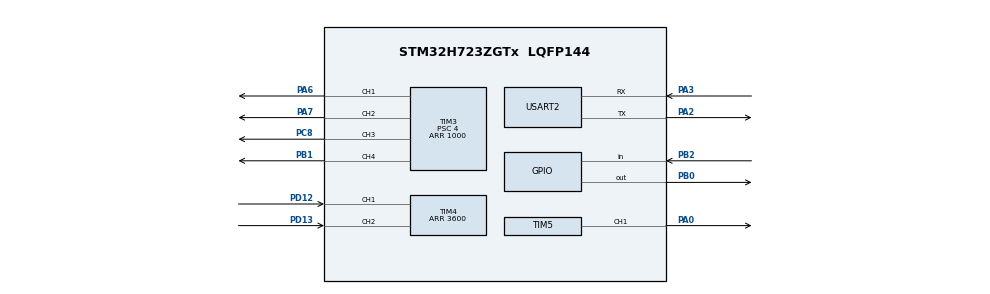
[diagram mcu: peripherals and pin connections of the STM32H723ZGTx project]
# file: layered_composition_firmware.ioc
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CORTEX_M7.default_mode_Activation=1
Dma.Request0=USART2_RX
Dma.Request1=USART2_TX
Dma.USART2_RX.0.Direction=DMA_PERIPH_TO_MEMORY
Dma.USART2_RX.0.EventEnable=DISABLE
Dma.USART2_RX.0.FIFOMode=DMA_FIFOMODE_DISABLE
Dma.USART2_RX.0.Instance=DMA1_Stream0
Dma.USART2_RX.0.MemDataAlignment=DMA_MDATAALIGN_BYTE
Dma.USART2_RX.0.MemInc=DMA_MINC_ENABLE
Dma.USART2_RX.0.Mode=DMA_CIRCULAR
Dma.USART2_RX.0.PeriphDataAlignment=DMA_PDATAALIGN_BYTE
Dma.USART2_RX.0.PeriphInc=DMA_PINC_DISABLE
Dma.USART2_RX.0.Polarity=HAL_DMAMUX_REQ_GEN_RISING
Dma.USART2_RX.0.Priority=DMA_PRIORITY_HIGH
Dma.USART2_RX.0.RequestNumber=1
Dma.USART2_RX.0.SignalID=NONE
Dma.USART2_RX.0.SyncEnable=DISABLE
Dma.USART2_RX.0.SyncPolarity=HAL_DMAMUX_SYNC_NO_EVENT
Dma.USART2_RX.0.SyncRequestNumber=1
Dma.USART2_RX.0.SyncSignalID=NONE
Dma.USART2_TX.1.Direction=DMA_MEMORY_TO_PERIPH
Dma.USART2_TX.1.EventEnable=DISABLE
Dma.USART2_TX.1.FIFOMode=DMA_FIFOMODE_DISABLE
Dma.USART2_TX.1.Instance=DMA1_Stream1
Dma.USART2_TX.1.MemDataAlignment=DMA_MDATAALIGN_BYTE
Dma.USART2_TX.1.MemInc=DMA_MINC_ENABLE
Dma.USART2_TX.1.Mode=DMA_NORMAL
Dma.USART2_TX.1.PeriphDataAlignment=DMA_PDATAALIGN_BYTE
Dma.USART2_TX.1.PeriphInc=DMA_PINC_DISABLE
Dma.USART2_TX.1.Polarity=HAL_DMAMUX_REQ_GEN_RISING
Dma.USART2_TX.1.Priority=DMA_PRIORITY_HIGH
Dma.USART2_TX.1.RequestNumber=1
Dma.USART2_TX.1.SignalID=NONE
Dma.USART2_TX.1.SyncEnable=DISABLE
Dma.USART2_TX.1.SyncPolarity=HAL_DMAMUX_SYNC_NO_EVENT
Dma.USART2_TX.1.SyncRequestNumber=1
Dma.USART2_TX.1.SyncSignalID=NONE
Mcu.Family=STM32H7
Mcu.Name=STM32H723ZGTx
Mcu.Package=LQFP144
NVIC.DMA1_Stream0_IRQn=true\:0\:0\:false\:false\:true\:false\:true\:true
NVIC.DMA1_Stream1_IRQn=true\:0\:0\:false\:false\:true\:false\:true\:true
NVIC.PriorityGroup=NVIC_PRIORITYGROUP_4
NVIC.USART2_IRQn=true\:0\:0\:false\:false\:true\:true\:true\:true
PA0.Signal=S_TIM5_CH1
PA13(JTMS/SWDIO).GPIO_Label=SWDIO
PA13(JTMS/SWDIO).Signal=DEBUG_JTMS-SWDIO
PA14(JTCK/SWCLK).GPIO_Label=SWCLK
PA14(JTCK/SWCLK).Signal=DEBUG_JTCK-SWCLK
PA2.Mode=Asynchronous
PA2.Signal=USART2_TX
PA3.Mode=Asynchronous
PA3.Signal=USART2_RX
PA6.Signal=S_TIM3_CH1
PA7.Signal=S_TIM3_CH2
PB0.Signal=GPIO_Output
PB1.Signal=S_TIM3_CH4
PB2.Signal=GPIO_Input
PC14-OSC32_IN.Signal=RCC_OSC32_IN
PC15-OSC32_OUT.Signal=RCC_OSC32_OUT
PC8.Signal=S_TIM3_CH3
PD12.Signal=S_TIM4_CH1
PD13.Signal=S_TIM4_CH2
ProjectManager.HeapSize=0x200
ProjectManager.StackSize=0x400
ProjectManager.TargetToolchain=STM32CubeIDE
RCC.ADCFreq_Value=608000000
RCC.APB1Freq_Value=48000000
RCC.APB2Freq_Value=48000000
RCC.APB3Freq_Value=48000000
RCC.APB4Freq_Value=48000000
RCC.CortexFreq_Value=192000000
RCC.D1PPRE=RCC_APB3_DIV2
RCC.D2PPRE1=RCC_APB1_DIV2
RCC.D2PPRE2=RCC_APB2_DIV2
RCC.D3PPRE=RCC_APB4_DIV2
RCC.DIVM1=4
RCC.DIVM2=1
RCC.DIVN1=12
RCC.DIVN2=19
RCC.DIVP1=1
RCC.DIVQ1=4
RCC.HCLKFreq_Value=96000000
RCC.HPRE=RCC_HCLK_DIV2
RCC.HSE_VALUE=8000000
RCC.PLLFRACN=0
RCC.SYSCLKFreq_VALUE=192000000
RCC.SYSCLKSource=RCC_SYSCLKSOURCE_PLLCLK
RCC.USBCLockSelection=RCC_USBCLKSOURCE_HSI48
RCC.USBFreq_Value=48000000
SH.S_TIM3_CH1.0=TIM3_CH1,PWM Generation1 CH1
SH.S_TIM3_CH2.0=TIM3_CH2,PWM Generation2 CH2
SH.S_TIM3_CH3.0=TIM3_CH3,PWM Generation3 CH3
SH.S_TIM3_CH4.0=TIM3_CH4,PWM Generation4 CH4
SH.S_TIM4_CH1.0=TIM4_CH1,Encoder_Interface
SH.S_TIM4_CH2.0=TIM4_CH2,Encoder_Interface
SH.S_TIM5_CH1.0=TIM5_CH1,PWM Generation1 CH1
TIM3.AutoReloadPreload=TIM_AUTORELOAD_PRELOAD_ENABLE
TIM3.Channel-PWM\ Generation1\ CH1=TIM_CHANNEL_1
TIM3.Channel-PWM\ Generation2\ CH2=TIM_CHANNEL_2
TIM3.Channel-PWM\ Generation3\ CH3=TIM_CHANNEL_3
TIM3.Channel-PWM\ Generation4\ CH4=TIM_CHANNEL_4
TIM3.Period=1000
TIM3.Prescaler=4
TIM4.AutoReloadPreload=TIM_AUTORELOAD_PRELOAD_ENABLE
TIM4.EncoderMode=TIM_ENCODERMODE_TI12
TIM4.Period=3600
TIM5.Channel-PWM\ Generation1\ CH1=TIM_CHANNEL_1
TIM5.Period=1000
TIM5.Prescaler=4
USART2.VirtualMode-Asynchronous=VM_ASYNC
VP_MEMORYMAP_VS_MEMORYMAP.Mode=CurAppReg
board=NUCLEO-H723ZG

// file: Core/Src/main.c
/* USER CODE BEGIN Header */
/**
 ******************************************************************************
 * @file           : main.c
 * @brief          : Main program body
 ******************************************************************************
 * @attention
 *
 * Copyright (c) 2026 STMicroelectronics.
 * All rights reserved.
 *
 * This software is licensed under terms that can be found in the LICENSE file
 * in the root directory of this software component.
 * If no LICENSE file comes with this software, it is provided AS-IS.
 *
 ******************************************************************************
 */
/* USER CODE END Header */
#include "main.h"

/* USER CODE BEGIN Includes */
#include "app/app_main.hpp"

// // 1. test
// #ifdef __cplusplus
// extern "C"
// {
// #endif
//   void test_main(void);
// #ifdef __cplusplus
// }
// #endif

// // 디버거 확인용 UART 수신 버퍼
// extern uint8_t uart_rx_buf_test[20];
// extern uint32_t uart_rx_index;

/* USER CODE END Includes */

TIM_HandleTypeDef htim3;
TIM_HandleTypeDef htim4;
TIM_HandleTypeDef htim5;

UART_HandleTypeDef huart2;
DMA_HandleTypeDef hdma_usart2_rx;
DMA_HandleTypeDef hdma_usart2_tx;

/* USER CODE BEGIN PV */
uint32_t main_cnt = 0;

/* USER CODE END PV */

void SystemClock_Config(void);
static void MPU_Config(void);
static void MX_GPIO_Init(void);
static void MX_DMA_Init(void);
static void MX_TIM3_Init(void);
static void MX_TIM4_Init(void);
static void MX_USART2_UART_Init(void);
static void MX_TIM5_Init(void);

int main(void)
{

  /* MPU Configuration--------------------------------------------------------*/
  MPU_Config();

  /* MCU Configuration--------------------------------------------------------*/

  /* Reset of all peripherals, Initializes the Flash interface and the Systick. */
  HAL_Init();

  /* Configure the system clock */
  SystemClock_Config();

  /* Initialize all configured peripherals */
  MX_GPIO_Init();
  MX_DMA_Init();
  MX_TIM3_Init();
  MX_TIM4_Init();
  MX_USART2_UART_Init();
  MX_TIM5_Init();
  /* USER CODE BEGIN 2 */
  app_init();
  /* USER CODE END 2 */

  /* Infinite loop */
  /* USER CODE BEGIN WHILE */
  while (1)
  {
    main_cnt++;

    // test_main();

    control_update();
    shoot_update();
    feeder_update();
    communication_update();

    HAL_Delay(10);
    /* USER CODE END WHILE */

  }
}

void SystemClock_Config(void)
{
  RCC_OscInitTypeDef RCC_OscInitStruct = {0};
  RCC_ClkInitTypeDef RCC_ClkInitStruct = {0};

  /** Supply configuration update enable
  */
  HAL_PWREx_ConfigSupply(PWR_LDO_SUPPLY);

  /** Configure the main internal regulator output voltage
  */
  __HAL_PWR_VOLTAGESCALING_CONFIG(PWR_REGULATOR_VOLTAGE_SCALE2);

  while(!__HAL_PWR_GET_FLAG(PWR_FLAG_VOSRDY)) {}

  /** Initializes the RCC Oscillators according to the specified parameters
  * in the RCC_OscInitTypeDef structure.
  */
  RCC_OscInitStruct.OscillatorType = RCC_OSCILLATORTYPE_HSI;
  RCC_OscInitStruct.HSIState = RCC_HSI_DIV1;
  RCC_OscInitStruct.HSICalibrationValue = 64;
  RCC_OscInitStruct.PLL.PLLState = RCC_PLL_ON;
  RCC_OscInitStruct.PLL.PLLSource = RCC_PLLSOURCE_HSI;
  RCC_OscInitStruct.PLL.PLLM = 4;
  RCC_OscInitStruct.PLL.PLLN = 12;
  RCC_OscInitStruct.PLL.PLLP = 1;
  RCC_OscInitStruct.PLL.PLLQ = 4;
  RCC_OscInitStruct.PLL.PLLR = 2;
  RCC_OscInitStruct.PLL.PLLRGE = RCC_PLL1VCIRANGE_3;
  RCC_OscInitStruct.PLL.PLLVCOSEL = RCC_PLL1VCOWIDE;
  RCC_OscInitStruct.PLL.PLLFRACN = 0;
  if (HAL_RCC_OscConfig(&RCC_OscInitStruct) != HAL_OK)
  {
    Error_Handler();
  }

  /** Initializes the CPU, AHB and APB buses clocks
  */
  RCC_ClkInitStruct.ClockType = RCC_CLOCKTYPE_HCLK|RCC_CLOCKTYPE_SYSCLK
                              |RCC_CLOCKTYPE_PCLK1|RCC_CLOCKTYPE_PCLK2
                              |RCC_CLOCKTYPE_D3PCLK1|RCC_CLOCKTYPE_D1PCLK1;
  RCC_ClkInitStruct.SYSCLKSource = RCC_SYSCLKSOURCE_PLLCLK;
  RCC_ClkInitStruct.SYSCLKDivider = RCC_SYSCLK_DIV1;
  RCC_ClkInitStruct.AHBCLKDivider = RCC_HCLK_DIV2;
  RCC_ClkInitStruct.APB3CLKDivider = RCC_APB3_DIV2;
  RCC_ClkInitStruct.APB1CLKDivider = RCC_APB1_DIV2;
  RCC_ClkInitStruct.APB2CLKDivider = RCC_APB2_DIV2;
  RCC_ClkInitStruct.APB4CLKDivider = RCC_APB4_DIV2;

  if (HAL_RCC_ClockConfig(&RCC_ClkInitStruct, FLASH_LATENCY_1) != HAL_OK)
  {
    Error_Handler();
  }
}

static void MX_TIM3_Init(void)
{

  TIM_MasterConfigTypeDef sMasterConfig = {0};
  TIM_OC_InitTypeDef sConfigOC = {0};

  htim3.Instance = TIM3;
  htim3.Init.Prescaler = 4;
  htim3.Init.CounterMode = TIM_COUNTERMODE_UP;
  htim3.Init.Period = 1000;
  htim3.Init.ClockDivision = TIM_CLOCKDIVISION_DIV1;
  htim3.Init.AutoReloadPreload = TIM_AUTORELOAD_PRELOAD_ENABLE;
  if (HAL_TIM_PWM_Init(&htim3) != HAL_OK)
  {
    Error_Handler();
  }
  sMasterConfig.MasterOutputTrigger = TIM_TRGO_RESET;
  sMasterConfig.MasterSlaveMode = TIM_MASTERSLAVEMODE_DISABLE;
  if (HAL_TIMEx_MasterConfigSynchronization(&htim3, &sMasterConfig) != HAL_OK)
  {
    Error_Handler();
  }
  sConfigOC.OCMode = TIM_OCMODE_PWM1;
  sConfigOC.Pulse = 0;
  sConfigOC.OCPolarity = TIM_OCPOLARITY_HIGH;
  sConfigOC.OCFastMode = TIM_OCFAST_DISABLE;
  if (HAL_TIM_PWM_ConfigChannel(&htim3, &sConfigOC, TIM_CHANNEL_1) != HAL_OK)
  {
    Error_Handler();
  }
  if (HAL_TIM_PWM_ConfigChannel(&htim3, &sConfigOC, TIM_CHANNEL_2) != HAL_OK)
  {
    Error_Handler();
  }
  if (HAL_TIM_PWM_ConfigChannel(&htim3, &sConfigOC, TIM_CHANNEL_3) != HAL_OK)
  {
    Error_Handler();
  }
  if (HAL_TIM_PWM_ConfigChannel(&htim3, &sConfigOC, TIM_CHANNEL_4) != HAL_OK)
  {
    Error_Handler();
  }
  HAL_TIM_MspPostInit(&htim3);

}

static void MX_TIM4_Init(void)
{

  TIM_Encoder_InitTypeDef sConfig = {0};
  TIM_MasterConfigTypeDef sMasterConfig = {0};

  htim4.Instance = TIM4;
  htim4.Init.Prescaler = 0;
  htim4.Init.CounterMode = TIM_COUNTERMODE_UP;
  htim4.Init.Period = 3600;
  htim4.Init.ClockDivision = TIM_CLOCKDIVISION_DIV1;
  htim4.Init.AutoReloadPreload = TIM_AUTORELOAD_PRELOAD_ENABLE;
  sConfig.EncoderMode = TIM_ENCODERMODE_TI12;
  sConfig.IC1Polarity = TIM_ICPOLARITY_RISING;
  sConfig.IC1Selection = TIM_ICSELECTION_DIRECTTI;
  sConfig.IC1Prescaler = TIM_ICPSC_DIV1;
  sConfig.IC1Filter = 0;
  sConfig.IC2Polarity = TIM_ICPOLARITY_RISING;
  sConfig.IC2Selection = TIM_ICSELECTION_DIRECTTI;
  sConfig.IC2Prescaler = TIM_ICPSC_DIV1;
  sConfig.IC2Filter = 0;
  if (HAL_TIM_Encoder_Init(&htim4, &sConfig) != HAL_OK)
  {
    Error_Handler();
  }
  sMasterConfig.MasterOutputTrigger = TIM_TRGO_RESET;
  sMasterConfig.MasterSlaveMode = TIM_MASTERSLAVEMODE_DISABLE;
  if (HAL_TIMEx_MasterConfigSynchronization(&htim4, &sMasterConfig) != HAL_OK)
  {
    Error_Handler();
  }

}

static void MX_TIM5_Init(void)
{

  TIM_MasterConfigTypeDef sMasterConfig = {0};
  TIM_OC_InitTypeDef sConfigOC = {0};

  htim5.Instance = TIM5;
  htim5.Init.Prescaler = 4;
  htim5.Init.CounterMode = TIM_COUNTERMODE_UP;
  htim5.Init.Period = 1000;
  htim5.Init.ClockDivision = TIM_CLOCKDIVISION_DIV1;
  htim5.Init.AutoReloadPreload = TIM_AUTORELOAD_PRELOAD_DISABLE;
  if (HAL_TIM_PWM_Init(&htim5) != HAL_OK)
  {
    Error_Handler();
  }
  sMasterConfig.MasterOutputTrigger = TIM_TRGO_RESET;
  sMasterConfig.MasterSlaveMode = TIM_MASTERSLAVEMODE_DISABLE;
  if (HAL_TIMEx_MasterConfigSynchronization(&htim5, &sMasterConfig) != HAL_OK)
  {
    Error_Handler();
  }
  sConfigOC.OCMode = TIM_OCMODE_PWM1;
  sConfigOC.Pulse = 0;
  sConfigOC.OCPolarity = TIM_OCPOLARITY_HIGH;
  sConfigOC.OCFastMode = TIM_OCFAST_DISABLE;
  if (HAL_TIM_PWM_ConfigChannel(&htim5, &sConfigOC, TIM_CHANNEL_1) != HAL_OK)
  {
    Error_Handler();
  }
  HAL_TIM_MspPostInit(&htim5);

}

static void MX_USART2_UART_Init(void)
{

  huart2.Instance = USART2;
  huart2.Init.BaudRate = 115200;
  huart2.Init.WordLength = UART_WORDLENGTH_8B;
  huart2.Init.StopBits = UART_STOPBITS_1;
  huart2.Init.Parity = UART_PARITY_NONE;
  huart2.Init.Mode = UART_MODE_TX_RX;
  huart2.Init.HwFlowCtl = UART_HWCONTROL_NONE;
  huart2.Init.OverSampling = UART_OVERSAMPLING_16;
  huart2.Init.OneBitSampling = UART_ONE_BIT_SAMPLE_DISABLE;
  huart2.Init.ClockPrescaler = UART_PRESCALER_DIV1;
  huart2.AdvancedInit.AdvFeatureInit = UART_ADVFEATURE_NO_INIT;
  if (HAL_UART_Init(&huart2) != HAL_OK)
  {
    Error_Handler();
  }
  if (HAL_UARTEx_SetTxFifoThreshold(&huart2, UART_TXFIFO_THRESHOLD_1_8) != HAL_OK)
  {
    Error_Handler();
  }
  if (HAL_UARTEx_SetRxFifoThreshold(&huart2, UART_RXFIFO_THRESHOLD_1_8) != HAL_OK)
  {
    Error_Handler();
  }
  if (HAL_UARTEx_DisableFifoMode(&huart2) != HAL_OK)
  {
    Error_Handler();
  }

}

static void MX_DMA_Init(void)
{

  /* DMA controller clock enable */
  __HAL_RCC_DMA1_CLK_ENABLE();

  /* DMA interrupt init */
  /* DMA1_Stream0_IRQn interrupt configuration */
  HAL_NVIC_SetPriority(DMA1_Stream0_IRQn, 0, 0);
  HAL_NVIC_EnableIRQ(DMA1_Stream0_IRQn);
  /* DMA1_Stream1_IRQn interrupt configuration */
  HAL_NVIC_SetPriority(DMA1_Stream1_IRQn, 0, 0);
  HAL_NVIC_EnableIRQ(DMA1_Stream1_IRQn);

}

static void MX_GPIO_Init(void)
{
  GPIO_InitTypeDef GPIO_InitStruct = {0};

  /* GPIO Ports Clock Enable */
  __HAL_RCC_GPIOC_CLK_ENABLE();
  __HAL_RCC_GPIOA_CLK_ENABLE();
  __HAL_RCC_GPIOB_CLK_ENABLE();
  __HAL_RCC_GPIOD_CLK_ENABLE();

  /*Configure GPIO pin Output Level */
  HAL_GPIO_WritePin(GPIOB, GPIO_PIN_0, GPIO_PIN_RESET);

  /*Configure GPIO pin : PB0 */
  GPIO_InitStruct.Pin = GPIO_PIN_0;
  GPIO_InitStruct.Mode = GPIO_MODE_OUTPUT_PP;
  GPIO_InitStruct.Pull = GPIO_NOPULL;
  GPIO_InitStruct.Speed = GPIO_SPEED_FREQ_LOW;
  HAL_GPIO_Init(GPIOB, &GPIO_InitStruct);

  /*Configure GPIO pin : PB2 */
  GPIO_InitStruct.Pin = GPIO_PIN_2;
  GPIO_InitStruct.Mode = GPIO_MODE_INPUT;
  GPIO_InitStruct.Pull = GPIO_NOPULL;
  HAL_GPIO_Init(GPIOB, &GPIO_InitStruct);

}

/* USER CODE BEGIN 4 */
void HAL_UART_RxCpltCallback(UART_HandleTypeDef *huart)
{
  // for test
  // if (huart->Instance == USART2)
  // {
  //   uart_rx_index++;
  //   uart_rx_index %= 20;
  //   HAL_UART_Receive_IT(&huart2, &uart_rx_buf_test[uart_rx_index], 1);
  // }

  if (huart->Instance == USART2)
  {
    comm_set_rx_done();
  }
}

/* USER CODE END 4 */

 /* MPU Configuration */

void MPU_Config(void)
{
  MPU_Region_InitTypeDef MPU_InitStruct = {0};

  /* Disables the MPU */
  HAL_MPU_Disable();

  /** Initializes and configures the Region and the memory to be protected
  */
  MPU_InitStruct.Enable = MPU_REGION_ENABLE;
  MPU_InitStruct.Number = MPU_REGION_NUMBER0;
  MPU_InitStruct.BaseAddress = 0x0;
  MPU_InitStruct.Size = MPU_REGION_SIZE_4GB;
  MPU_InitStruct.SubRegionDisable = 0x87;
  MPU_InitStruct.TypeExtField = MPU_TEX_LEVEL0;
  MPU_InitStruct.AccessPermission = MPU_REGION_NO_ACCESS;
  MPU_InitStruct.DisableExec = MPU_INSTRUCTION_ACCESS_DISABLE;
  MPU_InitStruct.IsShareable = MPU_ACCESS_SHAREABLE;
  MPU_InitStruct.IsCacheable = MPU_ACCESS_NOT_CACHEABLE;
  MPU_InitStruct.IsBufferable = MPU_ACCESS_NOT_BUFFERABLE;

  HAL_MPU_ConfigRegion(&MPU_InitStruct);
  /* Enables the MPU */
  HAL_MPU_Enable(MPU_PRIVILEGED_DEFAULT);

}

void Error_Handler(void)
{
  __disable_irq();
  while (1)
  {
  }
}
